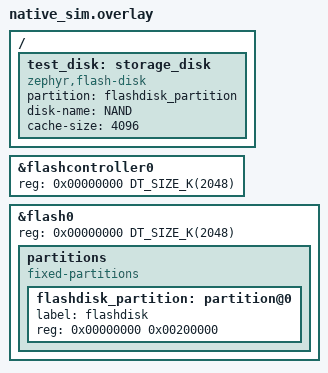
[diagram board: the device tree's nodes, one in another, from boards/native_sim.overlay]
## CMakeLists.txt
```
# SPDX-License-Identifier: Apache-2.0

cmake_minimum_required(VERSION 3.20.0)
find_package(Zephyr REQUIRED HINTS $ENV{ZEPHYR_BASE})
project(fat_fs_api)

target_sources(app PRIVATE
		src/common.c
		src/main.c
		src/test_fat_fs.c
		src/test_fat_dir.c
		src/test_fat_mount.c
		src/test_fat_rename.c
		src/test_fat_rename.c
		src/test_fat_rd_only_mount.c
		src/test_fat_file.c
		../common/test_fs_open_flags.c)
target_sources_ifdef(CONFIG_FLASH app PRIVATE
		../common/test_fs_mkfs.c
		src/test_fat_mkfs.c)
target_sources_ifdef(CONFIG_FS_FATFS_REENTRANT app PRIVATE
		src/test_fat_file_reentrant.c)
```

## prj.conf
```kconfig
CONFIG_FILE_SYSTEM=y
CONFIG_FILE_SYSTEM_MKFS=y
CONFIG_LOG=y
CONFIG_FAT_FILESYSTEM_ELM=y
CONFIG_DISK_DRIVER_FLASH=y
CONFIG_ZTEST=y
CONFIG_FLASH=y
CONFIG_FLASH_MAP=y
```

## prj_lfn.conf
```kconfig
CONFIG_FILE_SYSTEM=y
CONFIG_FILE_SYSTEM_MKFS=y
CONFIG_LOG=y
CONFIG_FAT_FILESYSTEM_ELM=y
CONFIG_FS_FATFS_LFN=y
CONFIG_DISK_DRIVER_FLASH=y
CONFIG_ZTEST=y
CONFIG_FLASH=y
CONFIG_FLASH_MAP=y
```

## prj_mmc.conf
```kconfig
CONFIG_FILE_SYSTEM=y
CONFIG_LOG=y
CONFIG_FAT_FILESYSTEM_ELM=y
CONFIG_SPI=y
CONFIG_GPIO=y
CONFIG_ZTEST=y
CONFIG_MMC_VOLUME_NAME="NAND"
CONFIG_MAIN_STACK_SIZE=4096
```

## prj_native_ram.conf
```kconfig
CONFIG_FILE_SYSTEM=y
CONFIG_FILE_SYSTEM_MKFS=y
CONFIG_LOG=y
CONFIG_FAT_FILESYSTEM_ELM=y
CONFIG_ZTEST=y
CONFIG_FLASH=y
CONFIG_FLASH_MAP=y
```

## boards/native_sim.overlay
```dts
/*
 * Copyright (c) 2022 Nordic Semiconductor ASA
 *
 * SPDX-License-Identifier: Apache-2.0
 */

&flashcontroller0 {
	reg = <0x00000000 DT_SIZE_K(2048)>;
};

&flash0 {
	reg = <0x00000000 DT_SIZE_K(2048)>;
	partitions {
		compatible = "fixed-partitions";
		#address-cells = <1>;
		#size-cells = <1>;

		flashdisk_partition: partition@0 {
			label = "flashdisk";
			reg = <0x00000000 0x00200000>;
		};
	};
};

/ {
	test_disk: storage_disk {
		compatible = "zephyr,flash-disk";
		partition = <&flashdisk_partition>;
		disk-name = "NAND";
		cache-size = <4096>;
	};
};
```

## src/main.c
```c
/*
 * Copyright (c) 2016 Intel Corporation.
 * Copyright (c) 2023 Husqvarna AB
 *
 * SPDX-License-Identifier: Apache-2.0
 */


#include "test_fat.h"
void test_fs_open_flags(void);
const char *test_fs_open_flags_file_path =  FATFS_MNTP"/the_file.txt";

static void *fat_fs_basic_setup(void)
{
	fs_file_t_init(&filep);
	test_fat_mount();
	test_fat_file();
	test_fat_dir();
	test_fat_fs();
	test_fat_rename();
	test_fs_open_flags();
#ifdef CONFIG_FS_FATFS_REENTRANT
	test_fat_file_reentrant();
#endif /* CONFIG_FS_FATFS_REENTRANT */
	test_fat_unmount();

	return NULL;
}
ZTEST_SUITE(fat_fs_basic, NULL, fat_fs_basic_setup, NULL, NULL, NULL);
```

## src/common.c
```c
/*
 * Copyright (c) 2016 Intel Corporation.
 * Copyright (c) 2023 Husqvarna AB
 *
 * SPDX-License-Identifier: Apache-2.0
 */

#include "test_fat.h"

/* FatFs work area */
FATFS fat_fs;
struct fs_file_t filep;
const char test_str[] = "hello world!";

int check_file_dir_exists(const char *path)
{
	int res;
	struct fs_dirent entry;

	/* Verify fs_stat() */
	res = fs_stat(path, &entry);

	return !res;
}
```

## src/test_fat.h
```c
/*
 * Copyright (c) 2016 Intel Corporation.
 * Copyright (c) 2020 Nordic Semiconductor ASA
 * Copyright (c) 2023 Husqvarna AB
 *
 * SPDX-License-Identifier: Apache-2.0
 */

#include <zephyr/kernel.h>
#include <zephyr/ztest.h>
#include <zephyr/fs/fs.h>
#include <ff.h>

#ifdef CONFIG_DISK_DRIVER_RAM
#define DISK_NAME "RAM"
#elif defined(CONFIG_DISK_DRIVER_FLASH)
#define DISK_NAME DT_PROP(DT_NODELABEL(test_disk), disk_name)
#elif defined(CONFIG_DISK_DRIVER_SDMMC)
#define DISK_NAME CONFIG_SDMMC_VOLUME_NAME
#elif defined(CONFIG_DISK_DRIVER_MMC)
#define DISK_NAME CONFIG_MMC_VOLUME_NAME
#else
#error "Failed to select DISK access type"
#endif

#define FATFS_MNTP	"/"DISK_NAME":"
#if defined(CONFIG_FS_FATFS_LFN)
#define TEST_FILE	FATFS_MNTP \
	"/testlongfilenamethatsmuchlongerthan8.3chars.text"
#else
#define TEST_FILE	FATFS_MNTP"/testfile.txt"
#endif /* CONFIG_FS_FATFS_LFN */
#define TEST_DIR	FATFS_MNTP"/testdir"
#define TEST_DIR_FILE	FATFS_MNTP"/testdir/testfile.txt"

extern struct fs_file_t filep;
extern const char test_str[];
/* FatFs work area */
extern FATFS fat_fs;

int check_file_dir_exists(const char *path);

void test_fat_mount(void);
void test_fat_unmount(void);
void test_fat_file(void);
void test_fat_dir(void);
void test_fat_fs(void);
void test_fat_rename(void);
#ifdef CONFIG_FS_FATFS_REENTRANT
void test_fat_file_reentrant(void);
#endif /* CONFIG_FS_FATFS_REENTRANT */
```

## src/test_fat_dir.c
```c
/*
 * Copyright (c) 2016 Intel Corporation.
 *
 * SPDX-License-Identifier: Apache-2.0
 */


#include "test_fat.h"
#include <stdio.h>

extern int test_file_write(void);
extern int test_file_close(void);
static int test_rmdir(void);

static int test_mkdir(void)
{
	int res;

	TC_PRINT("\nmkdir tests:\n");

	if (check_file_dir_exists(TEST_DIR)) {
		TC_PRINT("[%s] exists, delete it\n", TEST_DIR);
		if (test_rmdir()) {
			TC_PRINT("Error deleting dir %s\n", TEST_DIR);
			return TC_FAIL;
		}
	} else {
		TC_PRINT("Creating new dir %s\n", TEST_DIR);
	}

	/* Verify fs_mkdir() */
	res = fs_mkdir(TEST_DIR);
	if (res) {
		TC_PRINT("Error creating dir[%d]\n", res);
		return res;
	}

	res = fs_open(&filep, TEST_DIR_FILE, FS_O_CREATE | FS_O_RDWR);
	if (res) {
		TC_PRINT("Failed opening file [%d]\n", res);
		return res;
	}

	res = test_file_write();
	if (res) {
		return res;
	}

	res = fs_close(&filep);
	if (res) {
		TC_PRINT("Error closing file [%d]\n", res);
		return res;
	}

	TC_PRINT("Created dir %s!\n", TEST_DIR);

	return res;
}

static int test_lsdir(const char *path)
{
	int res;
	struct fs_dir_t dirp;
	struct fs_dirent entry;

	TC_PRINT("\nlsdir tests:\n");

	fs_dir_t_init(&dirp);

	/* Verify fs_opendir() */
	res = fs_opendir(&dirp, path);
	if (res) {
		TC_PRINT("Error opening dir %s [%d]\n", path, res);
		return res;
	}

	TC_PRINT("\nListing dir %s:\n", path);
	for (;;) {
		/* Verify fs_readdir() */
		res = fs_readdir(&dirp, &entry);

		/* entry.name[0] == 0 means end-of-dir */
		if (res || entry.name[0] == 0) {
			break;
		}

		if (entry.type == FS_DIR_ENTRY_DIR) {
			TC_PRINT("[DIR ] %s\n", entry.name);
		} else {
			TC_PRINT("[FILE] %s (size = %zu)\n",
				entry.name, entry.size);
		}
	}

	/* Verify fs_closedir() */
	fs_closedir(&dirp);

	return res;
}

static int test_rmdir(void)
{
	int res;
	struct fs_dir_t dirp;
	static struct fs_dirent entry;
	char file_path[80 + MAX_FILE_NAME];

	TC_PRINT("\nrmdir tests:\n");

	fs_dir_t_init(&dirp);

	if (!check_file_dir_exists(TEST_DIR)) {
		TC_PRINT("%s doesn't exist\n", TEST_DIR);
		return TC_FAIL;
	}

	res = fs_opendir(&dirp, TEST_DIR);
	if (res) {
		TC_PRINT("Error opening dir[%d]\n", res);
		return res;
	}

	TC_PRINT("\nRemoving files and sub directories in %s\n", TEST_DIR);
	for (;;) {
		res = fs_readdir(&dirp, &entry);

		/* entry.name[0] == 0 means end-of-dir */
		if (res || entry.name[0] == 0) {
			break;
		}

		/* Delete file or sub directory */
		sprintf(file_path, "%s/%s", TEST_DIR, entry.name);
		TC_PRINT("Removing %s\n", file_path);

		res = fs_unlink(file_path);
		if (res) {
			TC_PRINT("Error deleting file/dir [%d]\n", res);
			fs_closedir(&dirp);
			return res;
		}
	}

	fs_closedir(&dirp);

	/* Verify fs_unlink() */
	res = fs_unlink(TEST_DIR);
	if (res) {
		TC_PRINT("Error removing dir [%d]\n", res);
		return res;
	}

	TC_PRINT("Removed dir %s!\n", TEST_DIR);

	return res;
}

void test_fat_dir(void)
{
	zassert_true(test_mkdir() == TC_PASS);
	zassert_true(test_lsdir(FATFS_MNTP) == TC_PASS);
	zassert_true(test_lsdir(TEST_DIR) == TC_PASS);
	zassert_true(test_rmdir() == TC_PASS);
	zassert_true(test_lsdir(FATFS_MNTP) == TC_PASS);
}
```

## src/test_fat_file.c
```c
/*
 * Copyright (c) 2016 Intel Corporation.
 *
 * SPDX-License-Identifier: Apache-2.0
 */


#include "test_fat.h"
#include <string.h>

static int test_file_open(void)
{
	int res;

	TC_PRINT("\nOpen tests:\n");

	if (check_file_dir_exists(TEST_FILE)) {
		TC_PRINT("Opening existing file %s\n", TEST_FILE);
	} else {
		TC_PRINT("Creating new file %s\n", TEST_FILE);
	}

	/* Verify fs_open() */
	res = fs_open(&filep, TEST_FILE, FS_O_CREATE | FS_O_RDWR);
	if (res) {
		TC_PRINT("Failed opening file [%d]\n", res);
		return res;
	}

	TC_PRINT("Opened file %s\n", TEST_FILE);

	if (check_file_dir_exists(TEST_FILE)) {
		TC_PRINT("File now exists %s\n", TEST_FILE);
	}

	return res;
}

int test_file_write(void)
{
	ssize_t brw;
	int res;

	TC_PRINT("\nWrite tests:\n");

	/* Verify fs_seek() */
	res = fs_seek(&filep, 0, FS_SEEK_SET);
	if (res) {
		TC_PRINT("fs_seek failed [%d]\n", res);
		fs_close(&filep);
		return res;
	}

	TC_PRINT("Data written:\"%s\"\n\n", test_str);

	/* Verify fs_write() */
	brw = fs_write(&filep, (char *)test_str, strlen(test_str));
	if (brw < 0) {
		TC_PRINT("Failed writing to file [%zd]\n", brw);
		fs_close(&filep);
		return brw;
	}

	if (brw < strlen(test_str)) {
		TC_PRINT("Unable to complete write. Volume full.\n");
		TC_PRINT("Number of bytes written: [%zd]\n", brw);
		fs_close(&filep);
		return TC_FAIL;
	}

	TC_PRINT("Data successfully written!\n");

	return res;
}

static int test_file_sync(void)
{
	int res;

	TC_PRINT("\nSync tests:\n");

	/* Verify fs_sync() */
	res = fs_sync(&filep);
	if (res) {
		TC_PRINT("Error syncing file [%d]\n", res);
		return res;
	}

	return res;
}

static int test_file_read(void)
{
	ssize_t brw;
	int res;
	char read_buff[80];
	size_t sz = strlen(test_str);

	TC_PRINT("\nRead tests:\n");

	res = fs_seek(&filep, 0, FS_SEEK_SET);
	if (res) {
		TC_PRINT("fs_seek failed [%d]\n", res);
		fs_close(&filep);
		return res;
	}

	/* Verify fs_read() */
	brw = fs_read(&filep, read_buff, sz);
	if (brw < 0) {
		TC_PRINT("Failed reading file [%zd]\n", brw);
		fs_close(&filep);
		return brw;
	}

	read_buff[brw] = 0;

	TC_PRINT("Data read:\"%s\"\n\n", read_buff);

	if (strcmp(test_str, read_buff)) {
		TC_PRINT("Error - Data read does not match data written\n");
		TC_PRINT("Data read:\"%s\"\n\n", read_buff);
		return TC_FAIL;
	}

	TC_PRINT("Data read matches data written\n");

	return res;
}

static int test_file_truncate(void)
{
	int res;
	off_t orig_pos;
	char read_buff[80];
	ssize_t brw;

	TC_PRINT("\nTruncate tests:\n");

	/* Verify fs_truncate() */
	/* Test truncating to 0 size */
	TC_PRINT("\nTesting shrink to 0 size\n");
	res = fs_truncate(&filep, 0);
	if (res) {
		TC_PRINT("fs_truncate failed [%d]\n", res);
		fs_close(&filep);
		return res;
	}

	fs_seek(&filep, 0, FS_SEEK_END);
	/* Verify fs_tell() */
	if (fs_tell(&filep) > 0) {
		TC_PRINT("Failed truncating to size 0\n");
		fs_close(&filep);
		return TC_FAIL;
	}

	TC_PRINT("Testing write after truncating\n");
	res = test_file_write();
	if (res) {
		TC_PRINT("Write failed after truncating\n");
		return res;
	}

	fs_seek(&filep, 0, FS_SEEK_END);

	orig_pos = fs_tell(&filep);
	TC_PRINT("Original size of file = %ld\n", (long) orig_pos);

	/* Test shrinking file */
	TC_PRINT("\nTesting shrinking\n");
	res = fs_truncate(&filep, orig_pos - 5);
	if (res) {
		TC_PRINT("fs_truncate failed [%d]\n", res);
		fs_close(&filep);
		return res;
	}

	fs_seek(&filep, 0, FS_SEEK_END);
	TC_PRINT("File size after shrinking by 5 bytes = %ld\n",
						(long) fs_tell(&filep));
	if (fs_tell(&filep) != (orig_pos - 5)) {
		TC_PRINT("File size after fs_truncate not as expected\n");
		fs_close(&filep);
		return TC_FAIL;
	}

	/* Test expanding file */
	TC_PRINT("\nTesting expanding\n");
	fs_seek(&filep, 0, FS_SEEK_END);
	orig_pos = fs_tell(&filep);
	res = fs_truncate(&filep, orig_pos + 10);
	if (res) {
		TC_PRINT("fs_truncate failed [%d]\n", res);
		fs_close(&filep);
		return res;
	}

	fs_seek(&filep, 0, FS_SEEK_END);
	TC_PRINT("File size after expanding by 10 bytes = %ld\n",
						(long) fs_tell(&filep));
	if (fs_tell(&filep) != (orig_pos + 10)) {
		TC_PRINT("File size after fs_truncate not as expected\n");
		fs_close(&filep);
		return TC_FAIL;
	}

	/* Check if expanded regions are zeroed */
	TC_PRINT("Testing for zeroes in expanded region\n");
	fs_seek(&filep, -5, FS_SEEK_END);

	brw = fs_read(&filep, read_buff, 5);

	if (brw < 5) {
		TC_PRINT("Read failed after truncating\n");
		fs_close(&filep);
		return -1;
	}

	for (int i = 0; i < 5; i++) {
		if (read_buff[i]) {
			TC_PRINT("Expanded regions are not zeroed\n");
			fs_close(&filep);
			return TC_FAIL;
		}
	}

	return res;
}

int test_file_close(void)
{
	int res;

	TC_PRINT("\nClose tests:\n");

	res = fs_close(&filep);
	if (res) {
		TC_PRINT("Error closing file [%d]\n", res);
		return res;
	}

	TC_PRINT("Closed file %s\n", TEST_FILE);

	return res;
}

static int test_file_delete(void)
{
	int res;

	TC_PRINT("\nDelete tests:\n");

	/* Verify fs_unlink() */
	res = fs_unlink(TEST_FILE);
	if (res) {
		TC_PRINT("Error deleting file [%d]\n", res);
		return res;
	}

	/* Check if file was deleted */
	if (check_file_dir_exists(TEST_FILE)) {
		TC_PRINT("Failed deleting %s\n", TEST_FILE);
		return TC_FAIL;
	}

	TC_PRINT("File (%s) deleted successfully!\n", TEST_FILE);

	return res;
}

void test_fat_file(void)
{
	zassert_true(test_file_open() == TC_PASS);
	zassert_true(test_file_write() == TC_PASS);
	zassert_true(test_file_sync() == TC_PASS);
	zassert_true(test_file_read() == TC_PASS);
	zassert_true(test_file_truncate() == TC_PASS);
	zassert_true(test_file_close() == TC_PASS);
	zassert_true(test_file_delete() == TC_PASS);
}
```

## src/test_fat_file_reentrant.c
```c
/*
 * Copyright (c) 2023 Husqvarna AB
 *
 * SPDX-License-Identifier: Apache-2.0
 */

#include "test_fat.h"

#ifdef CONFIG_FS_FATFS_REENTRANT

#define REENTRANT_TEST_STACK_SIZE 500
#define SEMAPHORE_OP_SUCCESS 0
#define TEST_FILE2 FATFS_MNTP"/tfile2.txt"

void tlock_mutex(void *p1, void *p2, void *p3);
void tfile2_access(void *p1, void *p2, void *p3);

K_THREAD_STACK_DEFINE(tlock_mutex_stack_area, REENTRANT_TEST_STACK_SIZE);
K_THREAD_STACK_DEFINE(tfile2_access_stack_area, REENTRANT_TEST_STACK_SIZE);
struct k_thread tlock_mutex_data;
struct k_thread tfile2_access_data;
struct k_sem mutex_unlocked_sem;
struct k_sem run_non_thread_sem;

static int test_reentrant_access(void)
{
	int res;

	TC_PRINT("\nReentrant tests:\n");
	zassert_ok(k_sem_init(&mutex_unlocked_sem, 0, 1), NULL);
	zassert_ok(k_sem_init(&run_non_thread_sem, 0, 1), NULL);

	/* Start mutex locking thread */
	k_tid_t tid = k_thread_create(&tlock_mutex_data, tlock_mutex_stack_area,
			K_THREAD_STACK_SIZEOF(tlock_mutex_stack_area),
			tlock_mutex,
			NULL, NULL, NULL,
			K_PRIO_PREEMPT(0), 0, K_NO_WAIT);

	/* Make sure thread was able to lock mutex */
	k_sem_take(&run_non_thread_sem, K_FOREVER);

	/* File open should wait here, as the fs is locked. Therefore, automatic switch back to
	 * thread
	 */
	TC_PRINT("Open file\n");
	res = fs_open(&filep, TEST_FILE, FS_O_CREATE | FS_O_RDWR);
	zassert_ok(res, "Err: File could not be opened [%d]\n", res);
	TC_PRINT("File opened\n");

	/* Check if mutex thread really unlocked the mutexes */
	zassert_equal(SEMAPHORE_OP_SUCCESS, k_sem_take(&mutex_unlocked_sem, K_NO_WAIT),
		      "File open with locked mutex");

	/* Cleanup */
	res = fs_close(&filep);
	zassert_ok(res, "Error closing file [%d]\n", res);
	res = fs_unlink(TEST_FILE);
	zassert_ok(res, "Error deleting file [%d]\n", res);

	k_thread_join(tid, K_FOREVER);

	return res;
}

static int test_reentrant_parallel_file_access(void)
{
	int res;

	TC_PRINT("\nParallel reentrant-safe file access test:\n");

	TC_PRINT("Open file 1\n");
	res = fs_open(&filep, TEST_FILE, FS_O_CREATE | FS_O_RDWR);
	zassert_ok(res, "Err: File 1 could not be opened [%d]\n", res);
	TC_PRINT("File 1 opened 1\n");

	/* Start 2nd file acces thread */
	k_tid_t tid = k_thread_create(&tfile2_access_data, tfile2_access_stack_area,
				      K_THREAD_STACK_SIZEOF(tfile2_access_stack_area),
				      tfile2_access,
				      NULL, NULL, NULL,
				      K_PRIO_PREEMPT(0), 0, K_NO_WAIT);

	/* Wait for thread to finish accessing file 2 */
	k_thread_join(tid, K_FOREVER);

	/* Check existence of file 2 */
	struct fs_file_t filep2;

	fs_file_t_init(&filep2);

	TC_PRINT("Check file 2 existence\n");
	res = fs_open(&filep2, TEST_FILE2, FA_OPEN_EXISTING | FA_READ);
	zassert_ok(res, "Err: File 2 does not exist [%d]\n", res);

	/* Cleanup */
	res = fs_close(&filep2);
	zassert_ok(res, "Error closing file 2 [%d]\n", res);
	res = fs_unlink(TEST_FILE2);
	zassert_ok(res, "Error deleting file 2 [%d]\n", res);
	res = fs_close(&filep);
	zassert_ok(res, "Error closing file 1 [%d]\n", res);
	res = fs_unlink(TEST_FILE);
	zassert_ok(res, "Error deleting file 1 [%d]\n", res);

	return res;
}

void release_dirty_mutex(void)
{
	ff_mutex_give(fat_fs.ldrv);
}

int request_dirty_mutex(void)
{
	return ff_mutex_take(fat_fs.ldrv);
}

void tlock_mutex(void *p1, void *p2, void *p3)
{
	TC_PRINT("Mutex thread: Started, locking fs\n");
	request_dirty_mutex();
	TC_PRINT("Mutex thread: Lock acquired, yield to switch back to try to open file\n");
	k_sem_give(&run_non_thread_sem);
	k_yield();

	TC_PRINT("Mutex thread: Got back to thread, release mutex now and give semaphore to check "
		 "if file opened\n");
	k_sem_give(&mutex_unlocked_sem);
	release_dirty_mutex();

	TC_PRINT("Mutex thread: Lock released, thread terminating\n");
}

void tfile2_access(void *p1, void *p2, void *p3)
{
	int res;
	ssize_t brw;
	struct fs_file_t filep2;

	TC_PRINT("File 2 access thread started\n");

	/* Init fp for 2nd File for parallel access test */
	fs_file_t_init(&filep2);

	/* open 2nd file */
	TC_PRINT("Open file 2\n");
	res = fs_open(&filep2, TEST_FILE2, FS_O_CREATE | FS_O_RDWR);
	zassert_ok(res, "Err: File 2 could not be opened [%d]\n", res);
	TC_PRINT("File 2 opened 2\n");

	/* Verify fs_write() not locked */
	brw = fs_write(&filep2, (char *)test_str, strlen(test_str));
	if (brw < 0) {
		TC_PRINT("Failed writing to file [%zd]\n", brw);
		fs_close(&filep2);
		return;
	}

	if (brw < strlen(test_str)) {
		TC_PRINT("Unable to complete write. Volume full.\n");
		TC_PRINT("Number of bytes written: [%zd]\n", brw);
		fs_close(&filep2);
		return;
	}

	/* Close file and switch back to test context*/
	res = fs_close(&filep2);
	zassert_ok(res, "Error closing file [%d]\n", res);

	TC_PRINT("File 2 access thread successfully wrote to file 2\n");
}

void test_fat_file_reentrant(void)
{
	zassert_true(test_reentrant_access() == TC_PASS, NULL);
	zassert_true(test_reentrant_parallel_file_access() == TC_PASS, NULL);
}
#endif  /* CONFIG_FS_FATFS_REENTRANT */
```

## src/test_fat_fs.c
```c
/*
 * Copyright (c) 2016 Intel Corporation.
 *
 * SPDX-License-Identifier: Apache-2.0
 */

#include "test_fat.h"

static int test_statvfs(void)
{
	struct fs_statvfs stat;
	int res;

	/* Verify fs_statvfs() */
	res = fs_statvfs(FATFS_MNTP, &stat);
	if (res) {
		TC_PRINT("Error getting volume stats [%d]\n", res);
		return res;
	}

	TC_PRINT("\n");
	TC_PRINT("Optimal transfer block size   = %lu\n", stat.f_bsize);
	TC_PRINT("Allocation unit size          = %lu\n", stat.f_frsize);
	TC_PRINT("Volume size in f_frsize units = %lu\n", stat.f_blocks);
	TC_PRINT("Free space in f_frsize units  = %lu\n", stat.f_bfree);

	return TC_PASS;
}

void test_fat_fs(void)
{
	zassert_true(test_statvfs() == TC_PASS);
}
```

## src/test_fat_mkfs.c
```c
/*
 * Copyright (c) 2022 Antmicro
 *
 * SPDX-License-Identifier: Apache-2.0
 */


#include "test_fat.h"
#include <ff.h>
#ifdef CONFIG_DISK_DRIVER_FLASH
#include <zephyr/storage/flash_map.h>
#else
#include <zephyr/storage/disk_access.h>
#endif

/* mounting info */
static struct fs_mount_t fatfs_mnt = {
	.type = FS_FATFS,
	.mnt_point = "/"DISK_NAME":",
	.fs_data = &fat_fs,
};

void test_fs_mkfs_simple(void);
void test_fs_mkfs_ops(void);

struct fs_mount_t *fs_mkfs_mp = &fatfs_mnt;
const int fs_mkfs_type = FS_FATFS;
uintptr_t fs_mkfs_dev_id = (uintptr_t) DISK_NAME":";
int fs_mkfs_flags;
const char *some_file_path = "/"DISK_NAME":/SOME";
const char *other_dir_path = "/"DISK_NAME":/OTHER";

#ifdef CONFIG_DISK_DRIVER_FLASH
static int wipe_partition(void)
{
	/* In this test the first partition on flash device is used for FAT */
	unsigned int id = 0;
	const struct flash_area *pfa;
	int rc = flash_area_open(id, &pfa);

	if (rc < 0) {
		TC_PRINT("Error accessing flash area %u [%d]\n",
			 id, rc);
		return TC_FAIL;
	}

	TC_PRINT("Erasing %zu (0x%zx) bytes\n", pfa->fa_size, pfa->fa_size);
	rc = flash_area_flatten(pfa, 0, pfa->fa_size);
	(void)flash_area_close(pfa);

	if (rc < 0) {
		TC_PRINT("Error wiping flash area %u [%d]\n",
			 id, rc);
		return TC_FAIL;
	}

	return TC_PASS;
}
#else
static uint8_t erase_buffer[4096] = { 0 };

static int wipe_partition(void)
{
	uint32_t sector_size;
	uint32_t sector_count;
	uint32_t sector_wr_jmp;
	uint32_t sector_wr_size;

	if (disk_access_init(DISK_NAME)) {
		TC_PRINT("Failed to init disk "DISK_NAME"\n");
		return TC_FAIL;
	}
	if (disk_access_ioctl(DISK_NAME, DISK_IOCTL_GET_SECTOR_COUNT, &sector_count)) {
		TC_PRINT("Failed to get disk "DISK_NAME" sector count\n");
		return TC_FAIL;
	}
	if (disk_access_ioctl(DISK_NAME, DISK_IOCTL_GET_SECTOR_SIZE, &sector_size)) {
		TC_PRINT("Failed to get disk "DISK_NAME" sector size\n");
		return TC_FAIL;
	}

	if (sector_size > ARRAY_SIZE(erase_buffer)) {
		TC_PRINT("Predefined \"erase_buffer\" to small to handle single sector\n");
		return TC_FAIL;
	}

	sector_wr_size = MIN(sector_size, ARRAY_SIZE(erase_buffer));
	sector_wr_jmp = sector_wr_size / sector_wr_size;
	TC_PRINT("For "DISK_NAME" using sector write size "PRIu32" to write "PRIu32" at once\n",
		 sector_wr_size, sector_wr_jmp);

	for (uint32_t sector_idx = 0; sector_idx < sector_count; sector_idx += sector_wr_jmp) {
		if (disk_access_write(DISK_NAME, erase_buffer, sector_idx, 1)) {
			TC_PRINT("Faield to \"erase\" sector "PRIu32" to "DISK_NAME"\n",
				 sector_idx);
			return TC_FAIL;
		}
	}

	return TC_PASS;
}
#endif

ZTEST(fat_fs_mkfs, test_mkfs_simple)
{
	int ret;

	ret = wipe_partition();
	zassert_equal(ret, TC_PASS, "wipe partition failed %d", ret);

	test_fs_mkfs_simple();
}

ZTEST(fat_fs_mkfs, test_mkfs_ops)
{
	int ret;

	ret = wipe_partition();
	zassert_equal(ret, TC_PASS, "wipe partition failed %d", ret);

	test_fs_mkfs_ops();
}

static MKFS_PARM custom_cfg = {
	.fmt = FM_ANY | FM_SFD,	/* Any suitable FAT */
	.n_fat = 1,		/* One FAT fs table */
	.align = 0,		/* Get sector size via diskio query */
	.n_root = CONFIG_FS_FATFS_MAX_ROOT_ENTRIES,
	.au_size = 0		/* Auto calculate cluster size */
};

ZTEST(fat_fs_mkfs, test_mkfs_custom)
{
	int ret;
	struct fs_mount_t mp = fatfs_mnt;
	struct fs_statvfs sbuf;

	ret = wipe_partition();
	zassert_equal(ret, 0, "wipe partition failed %d", ret);

	ret = fs_mkfs(FS_FATFS, fs_mkfs_dev_id, &custom_cfg, 0);
	zassert_equal(ret, 0, "mkfs failed %d", ret);


	mp.flags = FS_MOUNT_FLAG_NO_FORMAT;
	ret = fs_mount(&mp);
	zassert_equal(ret, 0, "mount failed %d", ret);

	ret = fs_statvfs(mp.mnt_point, &sbuf);
	zassert_equal(ret, 0, "statvfs failed %d", ret);

	TC_PRINT("statvfs: %lu %lu %lu %lu",
			sbuf.f_bsize, sbuf.f_frsize, sbuf.f_blocks, sbuf.f_bfree);

	ret = fs_unmount(&mp);
	zassert_equal(ret, 0, "unmount failed %d", ret);
}

ZTEST_SUITE(fat_fs_mkfs, NULL, NULL, NULL, NULL, NULL);
```

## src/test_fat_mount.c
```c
/*
 * Copyright (c) 2018 Intel Corporation.
 * Copyright (c) 2020 Nordic Semiconductor ASA
 *
 * SPDX-License-Identifier: Apache-2.0
 */


#include "test_fat.h"

/* mounting info */
static struct fs_mount_t fatfs_mnt = {
	.type = FS_FATFS,
	.mnt_point = FATFS_MNTP,
	.fs_data = &fat_fs,
};

static int test_mount_no_format(void)
{
	int ret = 0;

	fatfs_mnt.flags = FS_MOUNT_FLAG_NO_FORMAT;
	ret = fs_mount(&fatfs_mnt);

	if (ret >= 0) {
		TC_PRINT("Expected failure\n");
		return TC_FAIL;
	}
	fatfs_mnt.flags = 0;

	return TC_PASS;
}

static int test_mount_rd_only_no_sys(void)
{
	int ret = 0;

	fatfs_mnt.flags = FS_MOUNT_FLAG_READ_ONLY;
	ret = fs_mount(&fatfs_mnt);

	if (ret >= 0) {
		TC_PRINT("Expected failure\n");
		return TC_FAIL;
	}
	fatfs_mnt.flags = 0;

	return TC_PASS;
}

static int test_mount_use_disk_access(void)
{
	int res;

	fatfs_mnt.flags = FS_MOUNT_FLAG_USE_DISK_ACCESS;
	res = fs_mount(&fatfs_mnt);
	if (res < 0) {
		TC_PRINT("Error mounting fs [%d]\n", res);
		return TC_FAIL;
	}
	return ((fatfs_mnt.flags & FS_MOUNT_FLAG_USE_DISK_ACCESS) ? TC_PASS : TC_FAIL);
}

static int test_mount(void)
{
	int res;

	fatfs_mnt.flags = 0;
	res = fs_mount(&fatfs_mnt);
	if (res < 0) {
		TC_PRINT("Error mounting fs [%d]\n", res);
		return TC_FAIL;
	}
	return ((fatfs_mnt.flags & FS_MOUNT_FLAG_USE_DISK_ACCESS) ? TC_PASS : TC_FAIL);
}

static int test_unmount(void)
{
	return (fs_unmount(&fatfs_mnt) >= 0 ? TC_PASS : TC_FAIL);
}

void test_fat_unmount(void)
{
	zassert_true(test_unmount() == TC_PASS);
}

void test_fat_mount(void)
{
	zassert_false(test_unmount() == TC_PASS);
	zassert_true(test_mount_no_format() == TC_PASS);
	zassert_true(test_mount_rd_only_no_sys() == TC_PASS);
	zassert_true(test_mount_use_disk_access() == TC_PASS);
	zassert_true(test_unmount() == TC_PASS);
	zassert_true(test_mount() == TC_PASS);
	zassert_false(test_mount() == TC_PASS);
}
```

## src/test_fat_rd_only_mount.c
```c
/*
 * Copyright (c) 2020 Nordic Semiconductor ASA
 *
 * SPDX-License-Identifier: Apache-2.0
 */


#include "test_fat.h"

/* mounting info */
static struct fs_mount_t fatfs_mnt = {
	.type = FS_FATFS,
	.mnt_point = FATFS_MNTP,
	.fs_data = &fat_fs,
};

static void test_prepare(void)
{
	struct fs_file_t fs;

	fs_file_t_init(&fs);
	zassert_equal(fs_mount(&fatfs_mnt), 0);
	zassert_equal(fs_open(&fs, FATFS_MNTP"/testfile.txt", FS_O_CREATE),
		      0, NULL);
	zassert_equal(fs_close(&fs), 0);
	zassert_equal(fs_unmount(&fatfs_mnt), 0);
}

static void test_unmount(void)
{
	zassert_true(fs_unmount(&fatfs_mnt) >= 0);
}

static void test_ops_on_rd(void)
{
	struct fs_file_t fs;
	int ret;

	fs_file_t_init(&fs);
	/* Check fs operation on volume mounted with FS_MOUNT_FLAG_READ_ONLY */
	fatfs_mnt.flags = FS_MOUNT_FLAG_READ_ONLY;
	TC_PRINT("Mount as read-only\n");
	ret = fs_mount(&fatfs_mnt);
	zassert_equal(ret, 0, "Expected success", ret);

	/* Attempt creating new file */
	ret = fs_open(&fs, FATFS_MNTP"/nosome", FS_O_CREATE);
	zassert_equal(ret, -EROFS, "Expected EROFS", ret);
	ret = fs_mkdir(FATFS_MNTP"/another");
	zassert_equal(ret, -EROFS, "Expected EROFS", ret);
	ret = fs_rename(FATFS_MNTP"/testfile.txt", FATFS_MNTP"/bestfile.txt");
	zassert_equal(ret, -EROFS, "Expected EROFS", ret);
	ret = fs_unlink(FATFS_MNTP"/testfile.txt");
	zassert_equal(ret, -EROFS, "Expected EROFS", ret);
	ret = fs_open(&fs, FATFS_MNTP"/testfile.txt", FS_O_RDWR);
	zassert_equal(ret, -EROFS, "Expected EROFS", ret);
	ret = fs_open(&fs, FATFS_MNTP"/testfile.txt", FS_O_READ);
	zassert_equal(ret, 0, "Expected success", ret);
	fs_close(&fs);
}

ZTEST(fat_fs_basic, test_fat_mount_rd_only)
{
	test_prepare();
	test_ops_on_rd();
	test_unmount();
}
```

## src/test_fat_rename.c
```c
/*
 * Copyright (c) 2018 Pushpal Sidhu
 *
 * SPDX-License-Identifier: Apache-2.0
 */



#include "test_fat.h"

static int delete_it(const char *path, int quiet)
{
	int res = 0;
	if (check_file_dir_exists(path)) {
		res = fs_unlink(path);
		if (res && !quiet) {
			TC_PRINT("Couldn't delete %s [%d]\n", path, res);
		}
	}

	return res;
}

static int create_file(const char *path)
{
	struct fs_file_t fp;
	int res = 0;

	fs_file_t_init(&fp);
	if (!check_file_dir_exists(path)) {
		res = fs_open(&fp, path, FS_O_CREATE | FS_O_RDWR);
		if (!res) {
			res = fs_close(&fp);
		} else {
			TC_PRINT("Couldn't open %s [%d]\n", path, res);
		}
	}

	return res;
}

static int create_dir(const char *path)
{
	int res = 0;
	if (!check_file_dir_exists(path)) {
		res = fs_mkdir(path);
		if (res) {
			TC_PRINT("Couldn't create %s [%d]\n", path, res);
		}
	}

	return res;
}


static int test_rename_dir(void)
{
	const char *dn = FATFS_MNTP"/td";
	const char *ndn = FATFS_MNTP"/ntd";
	int res = TC_FAIL;

	TC_PRINT("\nRename directory tests:\n");

	if (delete_it(dn, 0) || delete_it(ndn, 0)) {
		goto cleanup;
	}

	/* Rename non-existing dir to non-existing dir */
	res = fs_rename(dn, ndn);
	if (!res) {
		TC_PRINT("Renamed non-existent directory\n");
		res = TC_FAIL;
		goto cleanup;
	}

	/* Rename existing dir to non-existing dir */
	res = create_dir(dn);
	if (!!res) {
		goto cleanup;
	}

	res = fs_rename(dn, ndn);
	if (!!res ||
	    !check_file_dir_exists(ndn) ||
	    check_file_dir_exists(dn)) {
		TC_PRINT("Renaming %s to %s failed [%d]\n", dn, ndn, res);
		res = TC_FAIL;
		goto cleanup;
	}

	/* Rename existing file to existing file */
	create_file(dn);
	res = fs_rename(dn, ndn);
	if (!!res ||
	    !check_file_dir_exists(ndn) ||
	    check_file_dir_exists(dn)) {
		TC_PRINT("Renaming %s to %s failed [%d]\n", dn, ndn, res);
		res = TC_FAIL;
		goto cleanup;
	}

cleanup:
	delete_it(dn, 1);
	delete_it(ndn, 1);

	return res;
}

static int test_rename_file(void)
{
	const char *fn = FATFS_MNTP"/tf.txt";
	const char *nfn = FATFS_MNTP"/ntf.txt";
	int res = TC_FAIL;

	TC_PRINT("\nRename file tests:\n");

	if (delete_it(fn, 0) || delete_it(nfn, 0)) {
		goto cleanup;
	}

	/* Rename non-existing file to non-existing file */
	res = fs_rename(fn, nfn);
	if (!res) {
		TC_PRINT("Renamed non-existent file\n");
		res = TC_FAIL;
		goto cleanup;
	}

	/* Rename existing file to non-existing file */
	res = create_file(fn);
	if (!!res) {
		goto cleanup;
	}

	res = fs_rename(fn, nfn);
	if (!!res ||
	    !check_file_dir_exists(nfn) ||
	    check_file_dir_exists(fn)) {
		TC_PRINT("Renaming %s to %s failed [%d]\n", fn, nfn, res);
		res = TC_FAIL;
		goto cleanup;
	}

	/* Rename existing file to existing file */
	create_file(fn);
	res = fs_rename(fn, nfn);
	if (!!res ||
	    !check_file_dir_exists(nfn) ||
	    check_file_dir_exists(fn)) {
		TC_PRINT("Renaming %s to %s failed [%d]\n", fn, nfn, res);
		res = TC_FAIL;
		goto cleanup;
	}

cleanup:
	delete_it(fn, 1);
	delete_it(nfn, 1);

	return res;
}

void test_fat_rename(void)
{
	zassert_true(test_rename_file() == TC_PASS);
	zassert_true(test_rename_dir() == TC_PASS);
}
```
